# zeroer_ctrl: IP-XACT component
VLNV tenstorrent.com:ocah:zeroer_ctrl:1.0

## Address spaces and blocks
zeroer_ctrl_mmap.zeroer_ctrl: base 'h0, range 'h18, width 64

## Registers
Registers are 64-bit, read-write, reset 0x0 unless marked. A register's access mark holds for its fields unless they carry their own. Offsets are from the block's base; lines under a group give offsets from that group; [hi:lo] are bit positions; {n}, {i} and the like mark numbered series; 'fields as' and 'values as' point back to an identical list; <NAME> marks a mode.

## zeroer_ctrl_mmap.zeroer_ctrl — Control and status registers for the AXI memory-zeroing engine.
Base 0x00000000
0x00 DEST_ADDR
  [63:0] DEST_ADDR — Byte address to write zeros to. Bits at and above the master address width, 56 in the SMC, are ignored: a clear starts at the address truncated to that width. Program them as zero; the zeroer truncates an out-of-range value rather than rejecting it.
0x08 SIZE
  [63:0] SIZE — Size in bytes of zeros to write
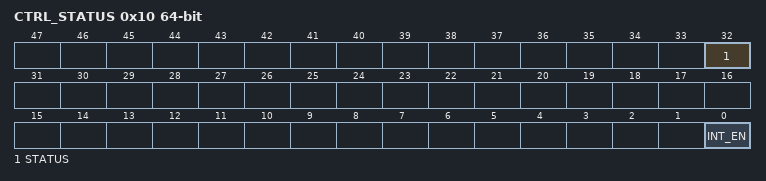
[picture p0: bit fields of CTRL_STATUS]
0x10 CTRL_STATUS access per field — Any write to this register triggers the start of the zeroer, irrespective of WSTRB, including a write with no byte lanes enabled. The start is ignored while SIZE is 0. DEST_ADDR and SIZE are captured when a clear starts; later writes to them do not affect the clear in progress. While a clear is still issuing write bursts, a write to this register completes on the bus but does not start a clear. Once the last burst of a clear has been issued, a write starts a new clear even while write responses of the previous clear are outstanding; STATUS then reads 1 across both clears, and the completion interrupt pulses once, when STATUS returns to 0. Wait for STATUS to read 0 before writing this register again.
  [32] STATUS ro — Indicates whether the zeroer is busy. 1 means the zeroer is active, has pending work, or is in an error state; 0 means it is idle with no pending or outstanding work, including after completion.
  [0] INT_EN rw — If enabled, an interrupt will be outputted once zeroer completes.

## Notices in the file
SPDX-License-Identifier: Apache-2.0
SPDX-FileCopyrightText: 2026 Tenstorrent USA, Inc.
